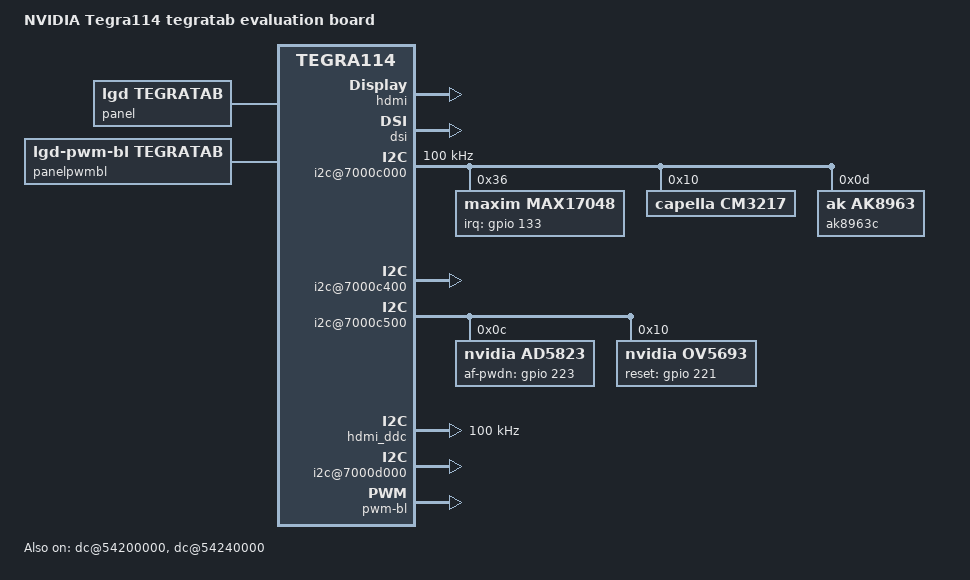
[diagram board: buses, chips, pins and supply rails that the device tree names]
/*
 * Copyright (c) 2013-2014, NVIDIA CORPORATION.  All rights reserved.
 *
 * This program is free software; you can redistribute it and/or modify it
 * under the terms and conditions of the GNU General Public License,
 * version 2, as published by the Free Software Foundation.
 *
 * This program is distributed in the hope it will be useful, but WITHOUT
 * ANY WARRANTY; without even the implied warranty of MERCHANTABILITY or
 * FITNESS FOR A PARTICULAR PURPOSE.  See the GNU General Public License for
 * more details.
 *
 * You should have received a copy of the GNU General Public License
 * along with this program.  If not, see <http://www.gnu.org/licenses/>.
 */

/dts-v1/;

/include/ "tegra114.dtsi"

/ {
	model = "NVIDIA Tegra114 tegratab evaluation board";
	compatible = "nvidia,tegratab", "nvidia,tegra114";

	gpio@6000d000 {
		status = "okay";
	};

	interrupt-controller@50041000 {
		status = "okay";
	};

	pinmux {
		pinctrl-names = "default";
		pinctrl-0 = <&state_default>;

		state_default: pinmux {
			clk1_out_pw4 {
				nvidia,pins = "clk1_out_pw4";
				nvidia,function = "extperiph1";
				nvidia,pull = <0>;
				nvidia,tristate = <0>;
				nvidia,enable-input = <0>;
			};
			dap1_din_pn1 {
				nvidia,pins = "dap1_din_pn1";
				nvidia,function = "i2s0";
				nvidia,pull = <0>;
				nvidia,tristate = <1>;
				nvidia,enable-input = <1>;
			};
			dap1_dout_pn2 {
				nvidia,pins = "dap1_dout_pn2",
						"dap1_fs_pn0",
						"dap1_sclk_pn3";
				nvidia,function = "i2s0";
				nvidia,pull = <0>;
				nvidia,tristate = <0>;
				nvidia,enable-input = <1>;
			};
			dap2_din_pa4 {
				nvidia,pins = "dap2_din_pa4";
				nvidia,function = "i2s1";
				nvidia,pull = <0>;
				nvidia,tristate = <1>;
				nvidia,enable-input = <1>;
			};
			dap2_dout_pa5 {
				nvidia,pins = "dap2_dout_pa5",
						"dap2_fs_pa2",
						"dap2_sclk_pa3";
				nvidia,function = "i2s1";
				nvidia,pull = <0>;
				nvidia,tristate = <0>;
				nvidia,enable-input = <1>;
			};
			dap4_din_pp5 {
				nvidia,pins = "dap4_din_pp5",
						"dap4_dout_pp6",
						"dap4_fs_pp4",
						"dap4_sclk_pp7";
				nvidia,function = "i2s3";
				nvidia,pull = <0>;
				nvidia,tristate = <0>;
				nvidia,enable-input = <1>;
			};
			dvfs_pwm_px0 {
				nvidia,pins = "dvfs_pwm_px0",
						"dvfs_clk_px2";
				nvidia,function = "cldvfs";
				nvidia,pull = <0>;
				nvidia,tristate = <0>;
				nvidia,enable-input = <0>;
			};
			ulpi_clk_py0 {
				nvidia,pins = "ulpi_clk_py0",
						"ulpi_data0_po1",
						"ulpi_data1_po2",
						"ulpi_data2_po3",
						"ulpi_data3_po4",
						"ulpi_data4_po5",
						"ulpi_data5_po6",
						"ulpi_data6_po7",
						"ulpi_data7_po0";
				nvidia,function = "ulpi";
				nvidia,pull = <0>;
				nvidia,tristate = <0>;
				nvidia,enable-input = <1>;
			};
			ulpi_dir_py1 {
				nvidia,pins = "ulpi_dir_py1",
						"ulpi_nxt_py2";
				nvidia,function = "ulpi";
				nvidia,pull = <0>;
				nvidia,tristate = <1>;
				nvidia,enable-input = <1>;
			};
			ulpi_stp_py3 {
				nvidia,pins = "ulpi_stp_py3";
				nvidia,function = "ulpi";
				nvidia,pull = <0>;
				nvidia,tristate = <0>;
				nvidia,enable-input = <0>;
			};
			cam_i2c_scl_pbb1 {
				nvidia,pins = "cam_i2c_scl_pbb1",
						"cam_i2c_sda_pbb2";
				nvidia,function = "i2c3";
				nvidia,pull = <0>;
				nvidia,tristate = <0>;
				nvidia,enable-input = <1>;
				nvidia,lock = <0>;
				nvidia,open-drain = <0>;
			};
			cam_mclk_pcc0 {
				nvidia,pins = "cam_mclk_pcc0",
						"pbb0";
				nvidia,function = "vi_alt3";
				nvidia,pull = <0>;
				nvidia,tristate = <0>;
				nvidia,enable-input = <0>;
				nvidia,lock = <0>;
			};
			gen2_i2c_scl_pt5 {
				nvidia,pins = "gen2_i2c_scl_pt5",
						"gen2_i2c_sda_pt6";
				nvidia,function = "i2c2";
				nvidia,pull = <0>;
				nvidia,tristate = <0>;
				nvidia,enable-input = <1>;
				nvidia,lock = <0>;
				nvidia,open-drain = <0>;
			};
			gmi_a16_pj7 {
				nvidia,pins = "gmi_a16_pj7";
				nvidia,function = "uartd";
				nvidia,pull = <0>;
				nvidia,tristate = <0>;
				nvidia,enable-input = <0>;
			};
			gmi_a17_pb0 {
				nvidia,pins = "gmi_a17_pb0",
						"gmi_a18_pb1";
				nvidia,function = "uartd";
				nvidia,pull = <0>;
				nvidia,tristate = <1>;
				nvidia,enable-input = <1>;
			};
			gmi_a19_pk7 {
				nvidia,pins = "gmi_a19_pk7";
				nvidia,function = "uartd";
				nvidia,pull = <0>;
				nvidia,tristate = <0>;
				nvidia,enable-input = <0>;
			};
			gmi_ad5_pg5 {
				nvidia,pins = "gmi_ad5_pg5",
						"gmi_cs6_n_pi3",
						"gmi_wr_n_pi0";
				nvidia,function = "spi4";
				nvidia,pull = <0>;
				nvidia,tristate = <0>;
				nvidia,enable-input = <1>;
			};
			gmi_ad6_pg6 {
				nvidia,pins = "gmi_ad6_pg6",
						"gmi_ad7_pg7";
				nvidia,function = "spi4";
				nvidia,pull = <2>;
				nvidia,tristate = <0>;
				nvidia,enable-input = <1>;
			};
			gmi_ad12_ph4 {
				nvidia,pins = "gmi_ad12_ph4";
				nvidia,function = "rsvd4";
				nvidia,pull = <0>;
				nvidia,tristate = <0>;
				nvidia,enable-input = <0>;
			};
			gmi_ad9_ph1 {
				nvidia,pins = "gmi_ad9_ph1";
				nvidia,function = "pwm1";
				nvidia,pull = <0>;
				nvidia,tristate = <0>;
				nvidia,enable-input = <0>;
			};
			gmi_cs1_n_pj2 {
				nvidia,pins = "gmi_cs1_n_pj2",
						"gmi_oe_n_pi1";
				nvidia,function = "soc";
				nvidia,pull = <0>;
				nvidia,tristate = <1>;
				nvidia,enable-input = <1>;
			};
			clk2_out_pw5 {
				nvidia,pins = "clk2_out_pw5";
				nvidia,function = "extperiph2";
				nvidia,pull = <0>;
				nvidia,tristate = <0>;
				nvidia,enable-input = <0>;
			};
			sdmmc1_clk_pz0 {
				nvidia,pins = "sdmmc1_clk_pz0";
				nvidia,function = "sdmmc1";
				nvidia,pull = <0>;
				nvidia,tristate = <0>;
				nvidia,enable-input = <1>;
			};
			sdmmc1_cmd_pz1 {
				nvidia,pins = "sdmmc1_cmd_pz1",
						"sdmmc1_dat0_py7",
						"sdmmc1_dat1_py6",
						"sdmmc1_dat2_py5",
						"sdmmc1_dat3_py4";
				nvidia,function = "sdmmc1";
				nvidia,pull = <2>;
				nvidia,tristate = <0>;
				nvidia,enable-input = <1>;
			};
			sdmmc1_wp_n_pv3 {
				nvidia,pins = "sdmmc1_wp_n_pv3";
				nvidia,function = "spi4";
				nvidia,pull = <2>;
				nvidia,tristate = <0>;
				nvidia,enable-input = <0>;
			};
			sdmmc3_clk_pa6 {
				nvidia,pins = "sdmmc3_clk_pa6";
				nvidia,function = "sdmmc3";
				nvidia,pull = <0>;
				nvidia,tristate = <0>;
				nvidia,enable-input = <1>;
			};
			sdmmc3_cmd_pa7 {
				nvidia,pins = "sdmmc3_cmd_pa7",
						"sdmmc3_dat0_pb7",
						"sdmmc3_dat1_pb6",
						"sdmmc3_dat2_pb5",
						"sdmmc3_dat3_pb4",
						"kb_col4_pq4",
						"sdmmc3_clk_lb_out_pee4",
						"sdmmc3_clk_lb_in_pee5";
				nvidia,function = "sdmmc3";
				nvidia,pull = <2>;
				nvidia,tristate = <0>;
				nvidia,enable-input = <1>;
			};
			sdmmc4_clk_pcc4 {
				nvidia,pins = "sdmmc4_clk_pcc4";
				nvidia,function = "sdmmc4";
				nvidia,pull = <0>;
				nvidia,tristate = <0>;
				nvidia,enable-input = <1>;
			};
			sdmmc4_cmd_pt7 {
				nvidia,pins = "sdmmc4_cmd_pt7",
						"sdmmc4_dat0_paa0",
						"sdmmc4_dat1_paa1",
						"sdmmc4_dat2_paa2",
						"sdmmc4_dat3_paa3",
						"sdmmc4_dat4_paa4",
						"sdmmc4_dat5_paa5",
						"sdmmc4_dat6_paa6",
						"sdmmc4_dat7_paa7";
				nvidia,function = "sdmmc4";
				nvidia,pull = <2>;
				nvidia,tristate = <0>;
				nvidia,enable-input = <1>;
			};
			clk_32k_out_pa0 {
				nvidia,pins = "clk_32k_out_pa0";
				nvidia,function = "blink";
				nvidia,pull = <0>;
				nvidia,tristate = <0>;
				nvidia,enable-input = <0>;
			};
			kb_col0_pq0 {
				nvidia,pins = "kb_col0_pq0",
						"kb_col1_pq1",
						"kb_col2_pq2",
						"kb_row0_pr0",
						"kb_row1_pr1",
						"kb_row2_pr2";
				nvidia,function = "kbc";
				nvidia,pull = <2>;
				nvidia,tristate = <0>;
				nvidia,enable-input = <1>;
			};
			dap3_din_pp1 {
				nvidia,pins = "dap3_din_pp1",
						"dap3_sclk_pp3";
				nvidia,function = "displayb";
				nvidia,pull = <0>;
				nvidia,tristate = <1>;
				nvidia,enable-input = <0>;
			};
			pv0 {
				nvidia,pins = "pv0";
				nvidia,function = "rsvd4";
				nvidia,pull = <0>;
				nvidia,tristate = <1>;
				nvidia,enable-input = <0>;
			};
			kb_row7_pr7 {
				nvidia,pins = "kb_row7_pr7";
				nvidia,function = "rsvd2";
				nvidia,pull = <2>;
				nvidia,tristate = <0>;
				nvidia,enable-input = <1>;
			};
			kb_row10_ps2 {
				nvidia,pins = "kb_row10_ps2";
				nvidia,function = "uarta";
				nvidia,pull = <0>;
				nvidia,tristate = <1>;
				nvidia,enable-input = <1>;
			};
			kb_row9_ps1 {
				nvidia,pins = "kb_row9_ps1";
				nvidia,function = "uarta";
				nvidia,pull = <0>;
				nvidia,tristate = <0>;
				nvidia,enable-input = <0>;
			};
			pwr_i2c_scl_pz6 {
				nvidia,pins = "pwr_i2c_scl_pz6",
						"pwr_i2c_sda_pz7";
				nvidia,function = "i2cpwr";
				nvidia,pull = <0>;
				nvidia,tristate = <0>;
				nvidia,enable-input = <1>;
				nvidia,lock = <0>;
				nvidia,open-drain = <0>;
			};
			sys_clk_req_pz5 {
				nvidia,pins = "sys_clk_req_pz5";
				nvidia,function = "sysclk";
				nvidia,pull = <0>;
				nvidia,tristate = <0>;
				nvidia,enable-input = <0>;
			};
			core_pwr_req {
				nvidia,pins = "core_pwr_req";
				nvidia,function = "pwron";
				nvidia,pull = <0>;
				nvidia,tristate = <0>;
				nvidia,enable-input = <0>;
			};
			cpu_pwr_req {
				nvidia,pins = "cpu_pwr_req";
				nvidia,function = "cpu";
				nvidia,pull = <0>;
				nvidia,tristate = <0>;
				nvidia,enable-input = <0>;
			};
			pwr_int_n {
				nvidia,pins = "pwr_int_n";
				nvidia,function = "pmi";
				nvidia,pull = <0>;
				nvidia,tristate = <1>;
				nvidia,enable-input = <1>;
			};
			reset_out_n {
				nvidia,pins = "reset_out_n";
				nvidia,function = "reset_out_n";
				nvidia,pull = <0>;
				nvidia,tristate = <0>;
				nvidia,enable-input = <0>;
			};
			clk3_out_pee0 {
				nvidia,pins = "clk3_out_pee0";
				nvidia,function = "extperiph3";
				nvidia,pull = <0>;
				nvidia,tristate = <0>;
				nvidia,enable-input = <0>;
			};
			gen1_i2c_scl_pc4 {
				nvidia,pins = "gen1_i2c_scl_pc4",
						"gen1_i2c_sda_pc5";
				nvidia,function = "i2c1";
				nvidia,pull = <0>;
				nvidia,tristate = <0>;
				nvidia,enable-input = <1>;
				nvidia,lock = <0>;
				nvidia,open-drain = <0>;
			};
			uart2_cts_n_pj5 {
				nvidia,pins = "uart2_cts_n_pj5";
				nvidia,function = "uartb";
				nvidia,pull = <0>;
				nvidia,tristate = <1>;
				nvidia,enable-input = <1>;
			};
			uart2_rts_n_pj6 {
				nvidia,pins = "uart2_rts_n_pj6";
				nvidia,function = "uartb";
				nvidia,pull = <0>;
				nvidia,tristate = <0>;
				nvidia,enable-input = <0>;
			};
			uart2_rxd_pc3 {
				nvidia,pins = "uart2_rxd_pc3";
				nvidia,function = "irda";
				nvidia,pull = <0>;
				nvidia,tristate = <1>;
				nvidia,enable-input = <1>;
			};
			uart2_txd_pc2 {
				nvidia,pins = "uart2_txd_pc2";
				nvidia,function = "irda";
				nvidia,pull = <0>;
				nvidia,tristate = <0>;
				nvidia,enable-input = <0>;
			};
			uart3_cts_n_pa1 {
				nvidia,pins = "uart3_cts_n_pa1",
						"uart3_rxd_pw7";
				nvidia,function = "uartc";
				nvidia,pull = <0>;
				nvidia,tristate = <1>;
				nvidia,enable-input = <1>;
			};
			uart3_rts_n_pc0 {
				nvidia,pins = "uart3_rts_n_pc0",
						"uart3_txd_pw6";
				nvidia,function = "uartc";
				nvidia,pull = <0>;
				nvidia,tristate = <0>;
				nvidia,enable-input = <0>;
			};
			owr {
				nvidia,pins = "owr";
				nvidia,function = "owr";
				nvidia,pull = <0>;
				nvidia,tristate = <0>;
				nvidia,enable-input = <1>;
			};
			hdmi_cec_pee3 {
				nvidia,pins = "hdmi_cec_pee3";
				nvidia,function = "cec";
				nvidia,pull = <0>;
				nvidia,tristate = <0>;
				nvidia,enable-input = <1>;
				nvidia,lock = <0>;
				nvidia,open-drain = <0>;
			};
			ddc_scl_pv4 {
				nvidia,pins = "ddc_scl_pv4",
						"ddc_sda_pv5";
				nvidia,function = "i2c4";
				nvidia,pull = <0>;
				nvidia,tristate = <0>;
				nvidia,enable-input = <1>;
				nvidia,lock = <0>;
				nvidia,rcv-sel = <1>;
			};
			spdif_in_pk6 {
				nvidia,pins = "spdif_in_pk6";
				nvidia,function = "usb";
				nvidia,pull = <2>;
				nvidia,tristate = <0>;
				nvidia,enable-input = <1>;
				nvidia,lock = <0>;
			};
			usb_vbus_en0_pn4 {
				nvidia,pins = "usb_vbus_en0_pn4";
				nvidia,function = "usb";
				nvidia,pull = <2>;
				nvidia,tristate = <0>;
				nvidia,enable-input = <1>;
				nvidia,lock = <0>;
				nvidia,open-drain = <1>;
			};
			gpio_x6_aud_px6 {
				nvidia,pins = "gpio_x6_aud_px6";
				nvidia,function = "spi6";
				nvidia,pull = <2>;
				nvidia,tristate = <1>;
				nvidia,enable-input = <1>;
			};
			gpio_x4_aud_px4 {
				nvidia,pins = "gpio_x4_aud_px4",
						"gpio_x7_aud_px7";
				nvidia,function = "rsvd1";
				nvidia,pull = <1>;
				nvidia,tristate = <0>;
				nvidia,enable-input = <0>;
			};
			gpio_x5_aud_px5 {
				nvidia,pins = "gpio_x5_aud_px5";
				nvidia,function = "rsvd1";
				nvidia,pull = <2>;
				nvidia,tristate = <0>;
				nvidia,enable-input = <1>;
			};
			gpio_w2_aud_pw2 {
				nvidia,pins = "gpio_w2_aud_pw2";
				nvidia,function = "rsvd2";
				nvidia,pull = <2>;
				nvidia,tristate = <0>;
				nvidia,enable-input = <1>;
			};
			gpio_w3_aud_pw3 {
				nvidia,pins = "gpio_w3_aud_pw3";
				nvidia,function = "spi6";
				nvidia,pull = <2>;
				nvidia,tristate = <0>;
				nvidia,enable-input = <1>;
			};
			gpio_x1_aud_px1 {
				nvidia,pins = "gpio_x1_aud_px1";
				nvidia,function = "rsvd4";
				nvidia,pull = <1>;
				nvidia,tristate = <0>;
				nvidia,enable-input = <1>;
			};
			gpio_x3_aud_px3 {
				nvidia,pins = "gpio_x3_aud_px3";
				nvidia,function = "rsvd4";
				nvidia,pull = <2>;
				nvidia,tristate = <0>;
				nvidia,enable-input = <1>;
			};
			dap3_fs_pp0 {
				nvidia,pins = "dap3_fs_pp0";
				nvidia,function = "i2s2";
				nvidia,pull = <1>;
				nvidia,tristate = <0>;
				nvidia,enable-input = <0>;
			};
			dap3_dout_pp2 {
				nvidia,pins = "dap3_dout_pp2";
				nvidia,function = "i2s2";
				nvidia,pull = <1>;
				nvidia,tristate = <0>;
				nvidia,enable-input = <0>;
			};
			pv1 {
				nvidia,pins = "pv1";
				nvidia,function = "rsvd1";
				nvidia,pull = <0>;
				nvidia,tristate = <0>;
				nvidia,enable-input = <1>;
			};
			pbb3 {
				nvidia,pins = "pbb3",
						"pbb5",
						"pbb6",
						"pbb7";
				nvidia,function = "rsvd4";
				nvidia,pull = <1>;
				nvidia,tristate = <0>;
				nvidia,enable-input = <0>;
			};
			pcc1 {
				nvidia,pins = "pcc1",
						"pcc2";
				nvidia,function = "rsvd4";
				nvidia,pull = <1>;
				nvidia,tristate = <0>;
				nvidia,enable-input = <1>;
			};
			gmi_ad0_pg0 {
				nvidia,pins = "gmi_ad0_pg0",
						"gmi_ad1_pg1";
				nvidia,function = "gmi";
				nvidia,pull = <0>;
				nvidia,tristate = <0>;
				nvidia,enable-input = <0>;
			};
			gmi_ad10_ph2 {
				nvidia,pins = "gmi_ad10_ph2",
						"gmi_ad11_ph3",
						"gmi_ad13_ph5",
						"gmi_ad8_ph0",
						"gmi_clk_pk1";
				nvidia,function = "gmi";
				nvidia,pull = <1>;
				nvidia,tristate = <0>;
				nvidia,enable-input = <0>;
			};
			gmi_ad2_pg2 {
				nvidia,pins = "gmi_ad2_pg2",
						"gmi_ad3_pg3";
				nvidia,function = "gmi";
				nvidia,pull = <0>;
				nvidia,tristate = <0>;
				nvidia,enable-input = <1>;
			};
			gmi_adv_n_pk0 {
				nvidia,pins = "gmi_adv_n_pk0",
						"gmi_cs0_n_pj0",
						"gmi_cs2_n_pk3",
						"gmi_cs4_n_pk2",
						"gmi_cs7_n_pi6",
						"gmi_dqs_p_pj3",
						"gmi_iordy_pi5",
						"gmi_wp_n_pc7";
				nvidia,function = "gmi";
				nvidia,pull = <2>;
				nvidia,tristate = <0>;
				nvidia,enable-input = <1>;
			};
			gmi_cs3_n_pk4 {
				nvidia,pins = "gmi_cs3_n_pk4";
				nvidia,function = "gmi";
				nvidia,pull = <2>;
				nvidia,tristate = <0>;
				nvidia,enable-input = <0>;
			};
			clk2_req_pcc5 {
				nvidia,pins = "clk2_req_pcc5";
				nvidia,function = "rsvd4";
				nvidia,pull = <0>;
				nvidia,tristate = <0>;
				nvidia,enable-input = <0>;
			};
			kb_col3_pq3 {
				nvidia,pins = "kb_col3_pq3",
						"kb_col6_pq6",
						"kb_col7_pq7";
				nvidia,function = "kbc";
				nvidia,pull = <2>;
				nvidia,tristate = <0>;
				nvidia,enable-input = <0>;
			};
			kb_col5_pq5 {
				nvidia,pins = "kb_col5_pq5";
				nvidia,function = "kbc";
				nvidia,pull = <2>;
				nvidia,tristate = <0>;
				nvidia,enable-input = <1>;
			};
			kb_row3_pr3 {
				nvidia,pins = "kb_row3_pr3",
						"kb_row4_pr4",
						"kb_row6_pr6",
						"kb_row8_ps0";
				nvidia,function = "kbc";
				nvidia,pull = <1>;
				nvidia,tristate = <0>;
				nvidia,enable-input = <1>;
			};
			clk3_req_pee1 {
				nvidia,pins = "clk3_req_pee1";
				nvidia,function = "rsvd4";
				nvidia,pull = <0>;
				nvidia,tristate = <0>;
				nvidia,enable-input = <0>;
			};
			pu4 {
				nvidia,pins = "pu4";
				nvidia,function = "displayb";
				nvidia,pull = <0>;
				nvidia,tristate = <0>;
				nvidia,enable-input = <0>;
			};
			pu5 {
				nvidia,pins = "pu5",
						"pu6";
				nvidia,function = "displayb";
				nvidia,pull = <0>;
				nvidia,tristate = <0>;
				nvidia,enable-input = <1>;
			};
			hdmi_int_pn7 {
				nvidia,pins = "hdmi_int_pn7";
				nvidia,function = "rsvd1";
				nvidia,pull = <1>;
				nvidia,tristate = <0>;
				nvidia,enable-input = <1>;
			};
			clk1_req_pee2 {
				nvidia,pins = "clk1_req_pee2",
						"usb_vbus_en1_pn5";
				nvidia,function = "rsvd4";
				nvidia,pull = <1>;
				nvidia,tristate = <1>;
				nvidia,enable-input = <0>;
			};

			drive_sdio1 {
				nvidia,pins = "drive_sdio1";
				nvidia,high-speed-mode = <1>;
				nvidia,schmitt = <0>;
				nvidia,low-power-mode = <3>;
				nvidia,pull-down-strength = <36>;
				nvidia,pull-up-strength = <20>;
				nvidia,slew-rate-rising = <2>;
				nvidia,slew-rate-falling = <2>;
			};
			drive_sdio3 {
				nvidia,pins = "drive_sdio3";
				nvidia,high-speed-mode = <1>;
				nvidia,schmitt = <0>;
				nvidia,low-power-mode = <3>;
				nvidia,pull-down-strength = <22>;
				nvidia,pull-up-strength = <36>;
				nvidia,slew-rate-rising = <0>;
				nvidia,slew-rate-falling = <0>;
			};
			drive_gma {
				nvidia,pins = "drive_gma";
				nvidia,high-speed-mode = <1>;
				nvidia,schmitt = <0>;
				nvidia,low-power-mode = <3>;
				nvidia,pull-down-strength = <2>;
				nvidia,pull-up-strength = <1>;
				nvidia,slew-rate-rising = <0>;
				nvidia,slew-rate-falling = <0>;
				nvidia,drive-type = <1>;
			};
		};
	};

	host1x {
		compatible = "nvidia,tegra114-host1x", "simple-bus";
		reg = <0x50000000 0x00024000>;
		interrupts = <0 65 0x04   /* mpcore syncpt */
			      0 67 0x04>; /* mpcore general */

		#address-cells = <1>;
		#size-cells = <1>;

		ranges = <0x54000000 0x54000000 0x01000000>;

		vi {
			compatible = "nvidia,tegra114-vi";
			reg = <0x54080000 0x00040000>;
		};

		epp {
			compatible = "nvidia,tegra114-epp";
			reg = <0x540c0000 0x00040000>;
		};

		isp {
			compatible = "nvidia,tegra114-isp";
			reg = <0x54100000 0x00040000>;
		};

		gr2d {
			compatible = "nvidia,tegra114-gr2d";
			reg = <0x54140000 0x00040000>;
		};

		gr3d {
			compatible = "nvidia,tegra114-gr3d";
			reg = <0x54180000 0x00040000>;
		};

		dc@54200000 {
			compatible = "nvidia,tegra114-dc";
			reg = <0x54200000 0x00040000>;
			interrupts = <0 73 0x04>;
			status = "disabled";

			rgb {
				status = "disabled";
			};
		};

		dc@54240000 {
			compatible = "nvidia,tegra114-dc";
			reg = <0x54240000 0x00040000>;
			interrupts = <0 74 0x04>;
			status = "disabled";

			rgb {
				status = "disabled";
			};
		};

		hdmi {
			compatible = "nvidia,tegra114-hdmi";
			reg = <0x54280000 0x00040000>;
			interrupts = <0 75 0x04>;
			status = "disabled";
		};

		tvo {
			compatible = "nvidia,tegra114-tvo";
			reg = <0x542c0000 0x00040000>;
			interrupts = <0 76 0x04>;
			status = "disabled";
		};

		dsi {
			compatible = "nvidia,tegra114-dsi";
			reg = <0x54300000 0x00040000>;
			status = "disabled";
		};

		msenc {
			compatible = "nvidia,tegra114-msenc";
			reg = <0x544c0000 0x00040000>;
		};

		tsec {
			compatible = "nvidia,tegra114-tsec";
			reg = <0x54500000 0x00040000>;
		};
	};

	/* GEN1 */
	i2c@7000c000 {
		status = "okay";

		max17048@36 {
			compatible = "maxim,max17048";
			reg = <0x36>;
			interrupt-parent = <&gpio>;
			interrupts = <133 0x04>;	/* gpio PQ5 */
			alert-threshold = <1>;		/* 1% SOC */
			one-percent-alerts = <1>;
			valert-max = <5100>;		/* not use */
			valert-min = <3240>;		/* 3.24V */
			vreset-threshold = <2400>;
			vreset-disable = <1>;		/* not use */
			hib-threshold = <48>;		/* 9.984%/hr */
			hib-active-threshold = <128>;	/* 160mV */
			bits = <19>;
			rcomp = <105>;
			rcomp-seg = <0x0080>;
			soccheck-a = <233>;
			soccheck-b = <235>;
			ocvtest = <55824>;
			minus_t_co_hot = <1125>;	/* -1.125 */
			minus_t_co_cold = <7625>;	/* -7.625 */
			data-tbl = <0xAA 0x30 0xB7 0x80 0xB8 0xD0 0xBA 0xC0
				0xBB 0xC0 0xBC 0x30 0xBC 0xB0 0xBD 0x60
				0xBE 0x10 0xBF 0x40 0xC0 0x30 0xC3 0x80
				0xC5 0x00 0xC7 0x60 0xCB 0x50 0xD0 0x10
				0x03 0x00 0x30 0xC0 0x1C 0x40 0x2C 0x00
				0x70 0xC0 0x51 0x40 0x43 0xE0 0x43 0xC0
				0x29 0xC0 0x2F 0xC0 0x17 0xE0 0x12 0xE0
				0x1C 0x20 0x13 0x80 0x0E 0x00 0x0E 0x00>;
			read_batt_id = <1>;
			set_current_threshold = "ina230";
			current_normal = <4500>;	/* 4.5A */
			current_threshold_num = <2>;
			current_threshold_soc = <4 8>;
			current_threshold = <1800 2500>;
			sysedp_throttle = "sysedp_lite";
			sysedp_throttle_num = <2>;
			sysedp_throttle_soc = <4 8>;
			sysedp_throttle_power = <10000 10500>;
		};
	};

	/* GEN2 */
	i2c@7000c400 {
		status = "okay";
	};

	/* CAM */
	i2c@7000c500 {
		status = "okay";
	};

	/* DDC */
	i2c@7000c700 {
		status = "okay";
	};

	/* PWR */
	i2c@7000d000 {
		status = "okay";
	};

	memory-controller@7001b000 {
		emc-table@12750 {
			compatible = "nvidia,tegra11-emc-table";
			reg = <12750>;
			clock-frequency = <12750>;
			nvidia,revision = <0x42>;
			nvidia,emc-min-mv = <900>;
			nvidia,source = "pll_p";
			nvidia,src-sel-reg = <0x4400003e>;
			nvidia,burst-regs-num = <100>;
			nvidia,emc-trimmers-num = <30>;
			nvidia,burst-up-down-regs-num = <11>;
			nvidia,emc-registers = <0x00000000 0x00000003
					0x00000000 0x00000000 0x00000000 0x00000004
					0x0000000a 0x00000003 0x0000000b 0x00000000
					0x00000000 0x00000003 0x00000001 0x00000000
					0x00000005 0x0000000f 0x00000006 0x00010000
					0x00000000 0x00000004 0x0000000f 0x00000060
					0x00000000 0x00000018 0x00000002 0x00000002
					0x00000001 0x00000000 0x00000007 0x0000000f
					0x00000005 0x00000005 0x00000004 0x00000004
					0x00000004 0x00000004 0x00000000 0x00000004
					0x00000005 0x00000064 0x00000005 0x00000020
					0x00000000 0x0000aa88 0x002c00a0 0x00008000
					0x00064000 0x00064000 0x00064000 0x00064000
					0x00000000 0x00000000 0x00000000 0x00000000
					0x00000000 0x00000000 0x00000000 0x00000000
					0x001112a0 0x00000000 0x0000a11c 0x00000000
					0x77ffc085 0x81f1f108 0x03037504 0x0000003f
					0x0000003f 0x00000007 0x02000000 0x00000802
					0x00000000 0x00000042 0x000c000c 0x000c000c
					0x00000000 0x00000000 0x00000000 0x00000000
					0x800001c5 0x1f7df7df 0x0000001f 0x40040001
					0x8000003f 0x00000001 0x00000001 0x00000002
					0x00000000 0x00000001 0x00000001 0x00000002
					0x00000008 0x00000002 0x00000001 0x00000003
					0x00000006 0x06030102 0x000a0402 0x77e30303
					0x001f0000 0x00040320>;
			nvidia,emc-trimmers-0 = <0x00000000 0x00000006
					0x00000006 0x00000004 0x00000004 0x00064000
					0x00000009 0x00000000 0x0000000d 0x00249249
					0x20820800 0x0007c000 0xa0f10f0f 0x00000000
					0x00000b0b 0x00000000 0x00000000 0x00000000
					0x00064000 0x00064000 0x00064000 0x0007c000
					0x0007c000 0x0007c000 0x00000000 0x00000000
					0x00000000 0x00000000 0x00000000 0x00000000>;
			nvidia,emc-trimmers-1 = <0x00000000 0x00000006
					0x00000006 0x00000004 0x00000004 0x00064000
					0x00000009 0x00000000 0x0000000d 0x00249249
					0x20820800 0x0007c000 0xa8f10f0f 0x00000000
					0x00000b0b 0x00000000 0x00000000 0x00000000
					0x00064000 0x00064000 0x00064000 0x0007c000
					0x0007c000 0x0007c000 0x00000000 0x00000000
					0x00000000 0x00000000 0x00000000 0x00000000>;
			nvidia,emc-burst-up-down-regs = <0x00000007 0x00ff00ff
					0x00ff00ff 0x00ff00ff 0x000000ff 0x00ff00ff
					0x00ff00ff 0x000000ff 0x00ff00ff 0x00ff00ff
					0x00ff00ff 0x4E564441 0x04010700 0x02000400
					12750>;
			nvidia,emc-zcal-cnt-long = <0x00000042>;
			nvidia,emc-acal-interval = <0x001fffff>;
			nvidia,emc-cfg = <0x7324000e>;
			nvidia,emc-mode-reset = <0x80001221>;
			nvidia,emc-mode-1 = <0x80100003>;
			nvidia,emc-mode-2 = <0x80200008>;
			nvidia,emc-mode-4 = <0x00000000>;
			nvidia,emc-clock-latency-change = <57820>;
		};
		emc-table@20400 {
			compatible = "nvidia,tegra11-emc-table";
			reg = <20400>;
			clock-frequency = <20400>;
			nvidia,revision = <0x42>;
			nvidia,emc-min-mv = <900>;
			nvidia,source = "pll_p";
			nvidia,src-sel-reg = <0x44000026>;
			nvidia,burst-regs-num = <100>;
			nvidia,emc-trimmers-num = <30>;
			nvidia,burst-up-down-regs-num = <11>;
			nvidia,emc-registers = <0x00000000 0x00000003
					0x00000000 0x00000000 0x00000000 0x00000004
					0x0000000a 0x00000003 0x0000000b 0x00000000
					0x00000000 0x00000003 0x00000001 0x00000000
					0x00000005 0x0000000f 0x00000006 0x00010000
					0x00000000 0x00000004 0x0000000f 0x0000009a
					0x00000000 0x00000026 0x00000002 0x00000002
					0x00000001 0x00000000 0x00000007 0x0000000f
					0x00000005 0x00000005 0x00000004 0x00000004
					0x00000004 0x00000004 0x00000000 0x00000004
					0x00000005 0x000000a0 0x00000005 0x00000020
					0x00000000 0x0000aa88 0x002c00a0 0x00008000
					0x00064000 0x00064000 0x00064000 0x00064000
					0x00000000 0x00000000 0x00000000 0x00000000
					0x00000000 0x00000000 0x00000000 0x00000000
					0x001112a0 0x00000000 0x0000a11c 0x00000000
					0x77ffc085 0x81f1f108 0x03037504 0x0000003f
					0x0000003f 0x0000000b 0x02000000 0x00000802
					0x00000000 0x00000042 0x000c000c 0x000c000c
					0x00000000 0x00000000 0x00000000 0x00000000
					0x8000023a 0x1f7df7df 0x0000001f 0x40020001
					0x80000046 0x00000001 0x00000001 0x00000002
					0x00000000 0x00000001 0x00000001 0x00000002
					0x00000008 0x00000002 0x00000001 0x00000003
					0x00000006 0x06030102 0x000a0402 0x75430303
					0x001f0000 0x00040320>;
			nvidia,emc-trimmers-0 = <0x00000000 0x00000006
					0x00000006 0x00000004 0x00000004 0x00064000
					0x00000009 0x00000000 0x0000000d 0x00249249
					0x20820800 0x0007c000 0xa0f10f0f 0x00000000
					0x00000b0b 0x00000000 0x00000000 0x00000000
					0x00064000 0x00064000 0x00064000 0x0007c000
					0x0007c000 0x0007c000 0x00000000 0x00000000
					0x00000000 0x00000000 0x00000000 0x00000000>;
			nvidia,emc-trimmers-1 = <0x00000000 0x00000006
					0x00000006 0x00000004 0x00000004 0x00064000
					0x00000009 0x00000000 0x0000000d 0x00249249
					0x20820800 0x0007c000 0xa8f10f0f 0x00000000
					0x00000b0b 0x00000000 0x00000000 0x00000000
					0x00064000 0x00064000 0x00064000 0x0007c000
					0x0007c000 0x0007c000 0x00000000 0x00000000
					0x00000000 0x00000000 0x00000000 0x00000000>;
			nvidia,emc-burst-up-down-regs = <0x0000000a 0x00ff00ff
					0x00ff00ff 0x00ff00ff 0x000000ff 0x00ff00ff
					0x00ff00ff 0x000000ff 0x00ff00ff 0x00ff00ff
					0x00ff00ff 0x4E564441 0x04010700 0x02000400
					20400>;
			nvidia,emc-zcal-cnt-long = <0x00000042>;
			nvidia,emc-acal-interval = <0x001fffff>;
			nvidia,emc-cfg = <0x7324000e>;
			nvidia,emc-mode-reset = <0x80001221>;
			nvidia,emc-mode-1 = <0x80100003>;
			nvidia,emc-mode-2 = <0x80200008>;
			nvidia,emc-mode-4 = <0x00000000>;
			nvidia,emc-clock-latency-change = <35610>;
		};
		emc-table@40800 {
			compatible = "nvidia,tegra11-emc-table";
			reg = <40800>;
			clock-frequency = <40800>;
			nvidia,revision = <0x42>;
			nvidia,emc-min-mv = <900>;
			nvidia,source = "pll_p";
			nvidia,src-sel-reg = <0x44000012>;
			nvidia,burst-regs-num = <100>;
			nvidia,emc-trimmers-num = <30>;
			nvidia,burst-up-down-regs-num = <11>;
			nvidia,emc-registers = <0x00000001 0x00000006
					0x00000000 0x00000001 0x00000000 0x00000004
					0x0000000a 0x00000003 0x0000000b 0x00000000
					0x00000000 0x00000003 0x00000001 0x00000000
					0x00000005 0x0000000f 0x00000006 0x00010000
					0x00000000 0x00000004 0x0000000f 0x00000134
					0x00000000 0x0000004d 0x00000002 0x00000002
					0x00000001 0x00000000 0x00000007 0x0000000f
					0x00000007 0x00000007 0x00000004 0x00000004
					0x00000004 0x00000004 0x00000000 0x00000004
					0x00000005 0x0000013f 0x00000005 0x00000020
					0x00000000 0x0000aa88 0x002c00a0 0x00008000
					0x00064000 0x00064000 0x00064000 0x00064000
					0x00000000 0x00000000 0x00000000 0x00000000
					0x00000000 0x00000000 0x00000000 0x00000000
					0x001112a0 0x00000000 0x0000a11c 0x00000000
					0x77ffc085 0x81f1f108 0x03037504 0x0000003f
					0x0000003f 0x00000015 0x02000000 0x00000802
					0x00000000 0x00000042 0x000c000c 0x000c000c
					0x00000000 0x00000000 0x00000000 0x00000000
					0x80000370 0x1f7df7df 0x0000001f 0xa0000001
					0x8000005b 0x00000001 0x00000001 0x00000002
					0x00000000 0x00000001 0x00000001 0x00000002
					0x00000008 0x00000002 0x00000001 0x00000003
					0x00000006 0x06030102 0x000a0402 0x73630303
					0x001f0000 0x00040320>;
			nvidia,emc-trimmers-0 = <0x00000000 0x00000006
					0x00000006 0x00000004 0x00000004 0x00064000
					0x00000009 0x00000000 0x0000000d 0x00249249
					0x20820800 0x0007c000 0xa0f10f0f 0x00000000
					0x00000b0b 0x00000000 0x00000000 0x00000000
					0x00064000 0x00064000 0x00064000 0x0007c000
					0x0007c000 0x0007c000 0x00000000 0x00000000
					0x00000000 0x00000000 0x00000000 0x00000000>;
			nvidia,emc-trimmers-1 = <0x00000000 0x00000006
					0x00000006 0x00000004 0x00000004 0x00064000
					0x00000009 0x00000000 0x0000000d 0x00249249
					0x20820800 0x0007c000 0xa8f10f0f 0x00000000
					0x00000b0b 0x00000000 0x00000000 0x00000000
					0x00064000 0x00064000 0x00064000 0x0007c000
					0x0007c000 0x0007c000 0x00000000 0x00000000
					0x00000000 0x00000000 0x00000000 0x00000000>;
			nvidia,emc-burst-up-down-regs = <0x00000015 0x00b000b0
					0x00b000c4 0x00d700eb 0x000000eb 0x00eb00eb
					0x00ff00eb 0x000000ff 0x00ff00ff 0x00ff00ff
					0x00ff00ff 0x4E564441 0x04010700 0x02000400
					40800>;
			nvidia,emc-zcal-cnt-long = <0x00000042>;
			nvidia,emc-acal-interval = <0x001fffff>;
			nvidia,emc-cfg = <0x7324000e>;
			nvidia,emc-mode-reset = <0x80001221>;
			nvidia,emc-mode-1 = <0x80100003>;
			nvidia,emc-mode-2 = <0x80200008>;
			nvidia,emc-mode-4 = <0x00000000>;
			nvidia,emc-clock-latency-change = <20850>;
		};
		emc-table@68000 {
			compatible = "nvidia,tegra11-emc-table";
			reg = <68000>;
			clock-frequency = <68000>;
			nvidia,revision = <0x42>;
			nvidia,emc-min-mv = <900>;
			nvidia,source = "pll_p";
			nvidia,src-sel-reg = <0x4400000a>;
			nvidia,burst-regs-num = <100>;
			nvidia,emc-trimmers-num = <30>;
			nvidia,burst-up-down-regs-num = <11>;
			nvidia,emc-registers = <0x00000003 0x0000000a
					0x00000000 0x00000002 0x00000000 0x00000004
					0x0000000a 0x00000003 0x0000000b 0x00000000
					0x00000000 0x00000003 0x00000001 0x00000000
					0x00000005 0x0000000f 0x00000006 0x00010000
					0x00000000 0x00000004 0x0000000f 0x00000202
					0x00000000 0x00000080 0x00000002 0x00000002
					0x00000001 0x00000000 0x00000008 0x0000000f
					0x0000000c 0x0000000c 0x00000004 0x00000004
					0x00000004 0x00000004 0x00000000 0x00000004
					0x00000005 0x00000213 0x00000005 0x00000020
					0x00000000 0x0000aa88 0x002c00a0 0x00008000
					0x00064000 0x00064000 0x00064000 0x00064000
					0x00000000 0x00000000 0x00000000 0x00000000
					0x00000000 0x00000000 0x00000000 0x00000000
					0x001112a0 0x00000000 0x0000a11c 0x00000000
					0x77ffc085 0x81f1f108 0x03037504 0x0000003f
					0x0000003f 0x00000022 0x02000000 0x00000802
					0x00000000 0x00000042 0x000c000c 0x000c000c
					0x00000000 0x00000000 0x00000000 0x00000000
					0x8000050e 0x1f7df7df 0x0000001f 0x00000001
					0x80000076 0x00000001 0x00000001 0x00000002
					0x00000000 0x00000001 0x00000001 0x00000002
					0x00000008 0x00000002 0x00000001 0x00000003
					0x00000006 0x06030102 0x000a0402 0x72c30403
					0x001f0000 0x00040320>;
			nvidia,emc-trimmers-0 = <0x00000000 0x00000006
					0x00000006 0x00000004 0x00000004 0x00064000
					0x00000009 0x00000000 0x0000000d 0x00249249
					0x20820800 0x0007c000 0xa0f10f0f 0x00000000
					0x00000b0b 0x00000000 0x00000000 0x00000000
					0x00064000 0x00064000 0x00064000 0x0007c000
					0x0007c000 0x0007c000 0x00000000 0x00000000
					0x00000000 0x00000000 0x00000000 0x00000000>;
			nvidia,emc-trimmers-1 = <0x00000000 0x00000006
					0x00000006 0x00000004 0x00000004 0x00064000
					0x00000009 0x00000000 0x0000000d 0x00249249
					0x20820800 0x0007c000 0xa8f10f0f 0x00000000
					0x00000b0b 0x00000000 0x00000000 0x00000000
					0x00064000 0x00064000 0x00064000 0x0007c000
					0x0007c000 0x0007c000 0x00000000 0x00000000
					0x00000000 0x00000000 0x00000000 0x00000000>;
			nvidia,emc-burst-up-down-regs = <0x00000023 0x00690069
					0x00690075 0x0081008d 0x0000008d 0x008d008d
					0x00bc008d 0x000000bc 0x00bc00bc 0x00ff00ff
					0x00ff00ff 0x4E564441 0x04010700 0x02000400
					68000>;
			nvidia,emc-zcal-cnt-long = <0x00000042>;
			nvidia,emc-acal-interval = <0x001fffff>;
			nvidia,emc-cfg = <0x7324000e>;
			nvidia,emc-mode-reset = <0x80001221>;
			nvidia,emc-mode-1 = <0x80100003>;
			nvidia,emc-mode-2 = <0x80200008>;
			nvidia,emc-mode-4 = <0x00000000>;
			nvidia,emc-clock-latency-change = <10720>;
		};
		emc-table@102000 {
			compatible = "nvidia,tegra11-emc-table";
			reg = <102000>;
			clock-frequency = <102000>;
			nvidia,revision = <0x42>;
			nvidia,emc-min-mv = <900>;
			nvidia,source = "pll_p";
			nvidia,src-sel-reg = <0x44000006>;
			nvidia,burst-regs-num = <100>;
			nvidia,emc-trimmers-num = <30>;
			nvidia,burst-up-down-regs-num = <11>;
			nvidia,emc-registers = <0x00000004 0x00000010
					0x00000000 0x00000003 0x00000001 0x00000004
					0x0000000a 0x00000003 0x0000000b 0x00000001
					0x00000001 0x00000003 0x00000001 0x00000000
					0x00000005 0x0000000f 0x00000006 0x00010000
					0x00000000 0x00000004 0x0000000f 0x00000303
					0x00000000 0x000000c0 0x00000002 0x00000002
					0x00000001 0x00000000 0x0000000d 0x0000000f
					0x00000012 0x00000012 0x00000004 0x00000004
					0x00000004 0x00000005 0x00000000 0x00000004
					0x00000005 0x0000031c 0x00000005 0x00000020
					0x00000000 0x0000aa88 0x002c00a0 0x00008000
					0x00064000 0x00064000 0x00064000 0x00064000
					0x00000000 0x00000000 0x00000000 0x00000000
					0x00000000 0x00000000 0x00000000 0x00000000
					0x001112a0 0x00000000 0x0000a11c 0x00000000
					0x77ffc085 0x81f1f108 0x03037504 0x0000003f
					0x0000003f 0x00000033 0x02000000 0x00000802
					0x00000000 0x00000042 0x000c000c 0x000c000c
					0x00000000 0x00000000 0x00000000 0x00000000
					0x80000713 0x1f7df7df 0x0000001f 0x08000001
					0x80000098 0x00000001 0x00000001 0x00000003
					0x00000000 0x00000002 0x00000001 0x00000002
					0x00000008 0x00000002 0x00000001 0x00000003
					0x00000006 0x06030102 0x000a0403 0x72830504
					0x001f0000 0x00040320>;
			nvidia,emc-trimmers-0 = <0x00000000 0x00000006
					0x00000006 0x00000004 0x00000004 0x00064000
					0x00000009 0x00000000 0x0000000d 0x00249249
					0x20820800 0x0007c000 0xa0f10f0f 0x00000000
					0x00000b0b 0x00000000 0x00000000 0x00000000
					0x00064000 0x00064000 0x00064000 0x0007c000
					0x0007c000 0x0007c000 0x00000000 0x00000000
					0x00000000 0x00000000 0x00000000 0x00000000>;
			nvidia,emc-trimmers-1 = <0x00000000 0x00000006
					0x00000006 0x00000004 0x00000004 0x00064000
					0x00000009 0x00000000 0x0000000d 0x00249249
					0x20820800 0x0007c000 0xa8f10f0f 0x00000000
					0x00000b0b 0x00000000 0x00000000 0x00000000
					0x00064000 0x00064000 0x00064000 0x0007c000
					0x0007c000 0x0007c000 0x00000000 0x00000000
					0x00000000 0x00000000 0x00000000 0x00000000>;
			nvidia,emc-burst-up-down-regs = <0x00000034 0x00460046
					0x0046004e 0x0056005e 0x0000005e 0x005e005e
					0x007d005e 0x0000007d 0x007d007d 0x00ff00ff
					0x00ff00ff 0x4E564441 0x04010700 0x02000400
					102000>;
			nvidia,emc-zcal-cnt-long = <0x00000042>;
			nvidia,emc-acal-interval = <0x001fffff>;
			nvidia,emc-cfg = <0x7324000e>;
			nvidia,emc-mode-reset = <0x80001221>;
			nvidia,emc-mode-1 = <0x80100003>;
			nvidia,emc-mode-2 = <0x80200008>;
			nvidia,emc-mode-4 = <0x00000000>;
			nvidia,emc-clock-latency-change = <6890>;
		};
		emc-table@204000 {
			compatible = "nvidia,tegra11-emc-table";
			reg = <204000>;
			clock-frequency = <204000>;
			nvidia,revision = <0x42>;
			nvidia,emc-min-mv = <900>;
			nvidia,source = "pll_p";
			nvidia,src-sel-reg = <0x44000002>;
			nvidia,burst-regs-num = <100>;
			nvidia,emc-trimmers-num = <30>;
			nvidia,burst-up-down-regs-num = <11>;
			nvidia,emc-registers = <0x00000009 0x00000020
					0x00000000 0x00000007 0x00000002 0x00000004
					0x0000000a 0x00000003 0x0000000b 0x00000002
					0x00000002 0x00000003 0x00000001 0x00000000
					0x00000005 0x0000000f 0x00000006 0x00010000
					0x00000000 0x00000004 0x0000000f 0x00000607
					0x00000000 0x00000181 0x00000002 0x00000002
					0x00000001 0x00000000 0x0000001d 0x0000000f
					0x00000023 0x00000023 0x00000004 0x00000004
					0x00000004 0x00000009 0x00000000 0x00000004
					0x00000005 0x00000638 0x00000006 0x00000020
					0x00000000 0x0000aa88 0x002c00a0 0x00008000
					0x00064000 0x00064000 0x00064000 0x00064000
					0x00000000 0x00000000 0x00000000 0x00000000
					0x00000000 0x00000000 0x00000000 0x00000000
					0x001112a0 0x00000000 0x0000a11c 0x00000000
					0x77ffc085 0x81f1f108 0x03037504 0x0000003f
					0x0000003f 0x00000000 0x02000000 0x00000802
					0x00020000 0x00000100 0x000c000c 0x000c000c
					0x00000000 0x00000000 0x00000000 0x00000000
					0x80000d22 0x1f7df7df 0x0000001f 0x01000003
					0x800000fe 0x00000001 0x00000001 0x00000005
					0x00000002 0x00000004 0x00000001 0x00000002
					0x00000008 0x00000002 0x00000001 0x00000003
					0x00000006 0x06030102 0x000a0405 0x72440a06
					0x001f0000 0x00040320>;
			nvidia,emc-trimmers-0 = <0x00000000 0x00000004
					0x00000007 0x00000004 0x00000004 0x00064000
					0x00000009 0x00000000 0x0000000d 0x00249249
					0x20820800 0x0007c000 0xa0f10f0f 0x00000000
					0x00000b0b 0x00000000 0x00000000 0x00000000
					0x00064000 0x00064000 0x00064000 0x0007c000
					0x0007c000 0x0007c000 0x00000000 0x00000000
					0x00000000 0x00000000 0x00000000 0x00000000>;
			nvidia,emc-trimmers-1 = <0x00000000 0x00000004
					0x00000007 0x00000004 0x00000004 0x00064000
					0x00000009 0x00000000 0x0000000d 0x00249249
					0x20820800 0x0007c000 0xa8f10f0f 0x00000000
					0x00000b0b 0x00000000 0x00000000 0x00000000
					0x00064000 0x00064000 0x00064000 0x0007c000
					0x0007c000 0x0007c000 0x00000000 0x00000000
					0x00000000 0x00000000 0x00000000 0x00000000>;
			nvidia,emc-burst-up-down-regs = <0x00000068 0x00230023
					0x00230027 0x002b002f 0x0000002f 0x002f002f
					0x003e002f 0x0000003e 0x003e003e 0x00ff00c8
					0x00ff00ff 0x4E564441 0x04010700 0x02000400
					204000>;
			nvidia,emc-zcal-cnt-long = <0x00000042>;
			nvidia,emc-acal-interval = <0x001fffff>;
			nvidia,emc-cfg = <0x7320000e>;
			nvidia,emc-mode-reset = <0x80001221>;
			nvidia,emc-mode-1 = <0x80100003>;
			nvidia,emc-mode-2 = <0x80200008>;
			nvidia,emc-mode-4 = <0x00000000>;
			nvidia,emc-clock-latency-change = <3420>;
		};
		emc-table@312000 {
			compatible = "nvidia,tegra11-emc-table";
			reg = <312000>;
			clock-frequency = <312000>;
			nvidia,revision = <0x42>;
			nvidia,emc-min-mv = <1000>;
			nvidia,source = "pll_c";
			nvidia,src-sel-reg = <0x24000002>;
			nvidia,burst-regs-num = <100>;
			nvidia,emc-trimmers-num = <30>;
			nvidia,burst-up-down-regs-num = <11>;
			nvidia,emc-registers = <0x0000000e 0x00000030
					0x00000000 0x00000009 0x00000003 0x00000004
					0x00000008 0x00000002 0x00000009 0x00000003
					0x00000003 0x00000002 0x00000001 0x00000000
					0x00000004 0x0000000f 0x00000006 0x00010000
					0x00000000 0x00000004 0x0000000f 0x00000941
					0x00000000 0x00000250 0x00000001 0x00000008
					0x00000001 0x00000000 0x0000002e 0x0000000e
					0x00000036 0x00000200 0x00000004 0x00000004
					0x00000004 0x0000000d 0x00000000 0x00000004
					0x00000005 0x00000982 0x00000000 0x00000020
					0x00000000 0x00005088 0x002c00a0 0x00008000
					0x00030000 0x00030000 0x00030000 0x00030000
					0x00000000 0x00000000 0x00000000 0x00000000
					0x00000000 0x00000000 0x00000000 0x00000000
					0x001112a0 0x00000000 0x0001013d 0x00000000
					0x77ffc085 0x81f1f108 0x03037504 0x00000000
					0x0000003f 0x00000000 0x02000000 0x00000802
					0x00020000 0x00000100 0x0190000c 0x0190000c
					0x00000000 0x00000000 0x00000000 0x00000000
					0x8000138d 0x1f7df7df 0x0000001f 0x0b000004
					0x8000016a 0x00000001 0x00000002 0x00000007
					0x00000004 0x00000006 0x00000001 0x00000002
					0x00000007 0x00000002 0x00000002 0x00000004
					0x00000006 0x06040202 0x000b0607 0x76e50f08
					0x001f0000 0x00040320>;
			nvidia,emc-trimmers-0 = <0x00000000 0x00000004
					0x00000006 0x00000005 0x00000004 0x00030000
					0x0000000b 0x00000000 0x0000000e 0x00249249
					0x20820800 0x0003c000 0xa0f10f0f 0x00048000
					0x00000909 0x00000000 0x00000000 0x00048000
					0x00030000 0x00030000 0x00030000 0x0003c000
					0x0003c000 0x0003c000 0x00000000 0x00000000
					0x00000000 0x00000000 0x00000000 0x00000000>;
			nvidia,emc-trimmers-1 = <0x00000000 0x00000004
					0x00000006 0x00000005 0x00000004 0x00030000
					0x0000000b 0x00000000 0x0000000e 0x00249249
					0x20820800 0x0003c000 0xa8f10f0f 0x00048000
					0x00000909 0x00000000 0x00000000 0x00048000
					0x00030000 0x00030000 0x00030000 0x0003c000
					0x0003c000 0x0003c000 0x00000000 0x00000000
					0x00000000 0x00000000 0x00000000 0x00000000>;
			nvidia,emc-burst-up-down-regs = <0x000000a0 0x00170017
					0x00170019 0x001c001e 0x0000001e 0x001e001e
					0x0029001e 0x00000029 0x00290029 0x00ff0082
					0x00ff00ff 0x4E564441 0x04010700 0x02000400
					312000>;
			nvidia,emc-zcal-cnt-long = <0x00000042>;
			nvidia,emc-acal-interval = <0x001fffff>;
			nvidia,emc-cfg = <0x5300000e>;
			nvidia,emc-mode-reset = <0x80000321>;
			nvidia,emc-mode-1 = <0x80100002>;
			nvidia,emc-mode-2 = <0x80200000>;
			nvidia,emc-mode-4 = <0x00000000>;
			nvidia,emc-clock-latency-change = <2180>;
		};
		emc-table@408000 {
			compatible = "nvidia,tegra11-emc-table";
			reg = <408000>;
			clock-frequency = <408000>;
			nvidia,revision = <0x42>;
			nvidia,emc-min-mv = <1000>;
			nvidia,source = "pll_p";
			nvidia,src-sel-reg = <0x44000000>;
			nvidia,burst-regs-num = <100>;
			nvidia,emc-trimmers-num = <30>;
			nvidia,burst-up-down-regs-num = <11>;
			nvidia,emc-registers = <0x00000012 0x00000040
					0x00000000 0x0000000d 0x00000004 0x00000005
					0x00000009 0x00000002 0x0000000c 0x00000004
					0x00000004 0x00000002 0x00000001 0x00000000
					0x00000004 0x0000000f 0x00000006 0x00010000
					0x00000000 0x00000004 0x00000010 0x00000c2e
					0x00000000 0x0000030b 0x00000001 0x00000008
					0x00000001 0x00000000 0x0000003d 0x00000011
					0x00000046 0x00000200 0x00000004 0x00000004
					0x00000004 0x00000011 0x00000000 0x00000004
					0x00000005 0x00000c6f 0x00000000 0x00000020
					0x00000000 0x00005088 0x002c0080 0x00008000
					0x00028000 0x00028000 0x00028000 0x00028000
					0x00000000 0x00000000 0x00000000 0x00000000
					0x00000000 0x00000000 0x00000000 0x00000000
					0x001112a0 0x00000000 0x0001013d 0x00000000
					0x77ffc085 0x81f1f108 0x03037504 0x00000000
					0x0000003f 0x00000000 0x02000000 0x00000802
					0x00020000 0x00000100 0x0181000c 0x0181000c
					0x00000000 0x00000000 0x00000000 0x00000000
					0x80001941 0x1f7df7df 0x0000001f 0x02000006
					0x80000190 0x00000001 0x00000002 0x0000000a
					0x00000006 0x00000008 0x00000001 0x00000002
					0x00000009 0x00000002 0x00000002 0x00000004
					0x00000006 0x06040202 0x000e070a 0x7547130b
					0x001f0000 0x00040320>;
			nvidia,emc-trimmers-0 = <0x00000000 0x00000004
					0x00000006 0x00000005 0x00000004 0x00028000
					0x0000000c 0x00000000 0x0000000e 0x00249249
					0x20820800 0x00028000 0xa0f10f0f 0x00028000
					0x00000606 0x00000000 0x00000000 0x00028000
					0x00028000 0x00028000 0x00028000 0x00028000
					0x00028000 0x00028000 0x00000000 0x00000000
					0x00000000 0x00000000 0x00000000 0x00000000>;
			nvidia,emc-trimmers-1 = <0x00000000 0x00000004
					0x00000006 0x00000005 0x00000004 0x00028000
					0x0000000c 0x00000000 0x0000000e 0x00249249
					0x20820800 0x00028000 0xa8f10f0f 0x00028000
					0x00000606 0x00000000 0x00000000 0x00028000
					0x00028000 0x00028000 0x00028000 0x00028000
					0x00028000 0x00028000 0x00000000 0x00000000
					0x00000000 0x00000000 0x00000000 0x00000000>;
			nvidia,emc-burst-up-down-regs = <0x000000d1 0x00110011
					0x00110013 0x00150017 0x00000017 0x00170017
					0x001f0017 0x0000001f 0x001f001f 0x00d30064
					0x00d300d3 0x4E564441 0x04010700 0x02000400
					408000>;
			nvidia,emc-zcal-cnt-long = <0x00000042>;
			nvidia,emc-acal-interval = <0x001fffff>;
			nvidia,emc-cfg = <0x53000006>;
			nvidia,emc-mode-reset = <0x80000731>;
			nvidia,emc-mode-1 = <0x80100002>;
			nvidia,emc-mode-2 = <0x80200008>;
			nvidia,emc-mode-4 = <0x00000000>;
			nvidia,emc-clock-latency-change = <1750>;
		};
		emc-table@528000 {
			compatible = "nvidia,tegra11-emc-table";
			reg = <528000>;
			clock-frequency = <528000>;
			nvidia,revision = <0x42>;
			nvidia,emc-min-mv = <1050>;
			nvidia,source = "pll_m";
			nvidia,src-sel-reg = <0x84000000>;
			nvidia,burst-regs-num = <100>;
			nvidia,emc-trimmers-num = <30>;
			nvidia,burst-up-down-regs-num = <11>;
			nvidia,emc-registers = <0x00000018 0x00000053
					0x00000000 0x00000011 0x00000006 0x00000006
					0x00000009 0x00000002 0x0000000d 0x00000006
					0x00000006 0x00000002 0x00000001 0x00000000
					0x00000005 0x0000000f 0x00000009 0x00010000
					0x00000000 0x00000006 0x00000012 0x00000fd6
					0x00000000 0x000003f5 0x00000002 0x0000000b
					0x00000001 0x00000000 0x00000050 0x00000012
					0x0000005a 0x00000200 0x00000004 0x00000004
					0x00000004 0x00000016 0x00000000 0x00000005
					0x00000006 0x00001017 0x00000000 0x00000020
					0x00000000 0x00005088 0xf0120091 0x00008000
					0x0000000a 0x0000000a 0x0000000a 0x0000000a
					0x00000000 0x00000000 0x00000000 0x00000000
					0x00000000 0x00000000 0x00000000 0x00000000
					0x001112a0 0x00000000 0x0000013d 0x00000000
					0x77ffc085 0x81f1f108 0x07077504 0x00000000
					0x0000003f 0x00000000 0x02000000 0x00000802
					0x00020000 0x00000100 0x016e000c 0x016e000c
					0x00000000 0x00000000 0x00000000 0x00000000
					0x80002062 0x1f7df7df 0x0000001f 0x0f000007
					0x80000190 0x00000002 0x00000003 0x0000000d
					0x00000008 0x0000000a 0x00000001 0x00000002
					0x00000009 0x00000002 0x00000002 0x00000005
					0x00000006 0x06050202 0x0010090d 0x7428180e
					0x001f0000 0x00040320>;
			nvidia,emc-trimmers-0 = <0x00000000 0x00000006
					0x00000008 0x00000007 0x00000004 0x0000000a
					0x0000000c 0x00000000 0x00000010 0x00249249
					0x20820800 0x0000000c 0xa0f10f0f 0x00000010
					0x00000909 0x00000000 0x00000000 0x00000010
					0x0000000a 0x0000000a 0x0000000a 0x0000000c
					0x0000000c 0x0000000c 0x00000000 0x00000000
					0x00000000 0x00000000 0x00000000 0x00000000>;
			nvidia,emc-trimmers-1 = <0x00000000 0x00000006
					0x00000008 0x00000007 0x00000004 0x0000000a
					0x0000000c 0x00000000 0x00000010 0x00249249
					0x20820800 0x0000000c 0xa8f10f0f 0x00000010
					0x00000909 0x00000000 0x00000000 0x00000010
					0x0000000a 0x0000000a 0x0000000a 0x0000000c
					0x0000000c 0x0000000c 0x00000000 0x00000000
					0x00000000 0x00000000 0x00000000 0x00000000>;
			nvidia,emc-burst-up-down-regs = <0x0000010e 0x000d000d
					0x000d000f 0x00100012 0x00000012 0x00120012
					0x00180012 0x00000018 0x00180018 0x00a3004d
					0x00a300a3 0x4E564441 0x04010700 0x02000400
					528000>;
			nvidia,emc-zcal-cnt-long = <0x00000042>;
			nvidia,emc-acal-interval = <0x001fffff>;
			nvidia,emc-cfg = <0x53000004>;
			nvidia,emc-mode-reset = <0x80000941>;
			nvidia,emc-mode-1 = <0x80100002>;
			nvidia,emc-mode-2 = <0x80200008>;
			nvidia,emc-mode-4 = <0x00000000>;
			nvidia,emc-clock-latency-change = <1440>;
		};
		emc-table@624000 {
			compatible = "nvidia,tegra11-emc-table";
			reg = <624000>;
			clock-frequency = <624000>;
			nvidia,revision = <0x42>;
			nvidia,emc-min-mv = <1100>;
			nvidia,source = "pll_c";
			nvidia,src-sel-reg = <0x24000000>;
			nvidia,burst-regs-num = <100>;
			nvidia,emc-trimmers-num = <30>;
			nvidia,burst-up-down-regs-num = <11>;
			nvidia,emc-registers = <0x0000001d 0x00000062
					0x00000000 0x00000014 0x00000007 0x00000007
					0x0000000b 0x00000003 0x00000010 0x00000007
					0x00000007 0x00000003 0x00000001 0x00000000
					0x00000005 0x0000000f 0x0000000a 0x00010000
					0x00000000 0x00000007 0x00000014 0x000012c3
					0x00000000 0x000004b0 0x00000002 0x0000000d
					0x00000001 0x00000000 0x0000005d 0x00000015
					0x0000006b 0x00000200 0x00000005 0x00000005
					0x00000005 0x00000019 0x00000000 0x00000006
					0x00000007 0x00001304 0x00000009 0x80000000
					0x00000000 0x0000ba88 0xf00d0191 0x00008000
					0x007fc008 0x007fc008 0x007fc008 0x007fc008
					0x00000000 0x00000000 0x00000000 0x00000000
					0x00000000 0x00000000 0x00000000 0x00000000
					0x001112a0 0x00000000 0x0000013d 0x00000000
					0x77ffc085 0x81f1f108 0x07077504 0x00000000
					0x0000003f 0x00000000 0x02000000 0x00000802
					0x00020000 0x00000100 0x0161000c 0x0161000c
					0x00000000 0x00000000 0x00000000 0x00000000
					0x80002617 0x1f7df7df 0x0000001f 0x06000009
					0x80000190 0x00000003 0x00000004 0x0000000f
					0x00000009 0x0000000c 0x00000002 0x00000003
					0x0000000b 0x00000002 0x00000002 0x00000005
					0x00000007 0x07050202 0x00130b0f 0x736a1d10
					0x001f0000 0x00040320>;
			nvidia,emc-trimmers-0 = <0x00000000 0x00000006
					0x00000009 0x00000008 0x00000004 0x007fc008
					0x0000000c 0x00000000 0x00000012 0x00249249
					0x20820800 0x0000000b 0xa0f10f0f 0x00000000
					0x00000909 0x00000000 0x00000000 0x00000000
					0x007fc008 0x007fc008 0x007fc008 0x0000000b
					0x0000000b 0x0000000b 0x00000000 0x00000000
					0x00000000 0x00000000 0x00000000 0x00000000>;
			nvidia,emc-trimmers-1 = <0x00000000 0x00000006
					0x00000009 0x00000008 0x00000004 0x007fc008
					0x0000000c 0x00000000 0x00000012 0x00249249
					0x20820800 0x0000000b 0xa8f10f0f 0x00000000
					0x00000909 0x00000000 0x00000000 0x00000000
					0x007fc008 0x007fc008 0x007fc008 0x0000000b
					0x0000000b 0x0000000b 0x00000000 0x00000000
					0x00000000 0x00000000 0x00000000 0x00000000>;
			nvidia,emc-burst-up-down-regs = <0x0000013f 0x000b000b
					0x000b000c 0x000e000f 0x0000000f 0x000f000f
					0x0014000f 0x00000014 0x00140014 0x008a0041
					0x008a008a 0x4E564441 0x04010700 0x02000400
					624000>;
			nvidia,emc-zcal-cnt-long = <0x00000042>;
			nvidia,emc-acal-interval = <0x001fffff>;
			nvidia,emc-cfg = <0x53200000>;
			nvidia,emc-mode-reset = <0x80000b61>;
			nvidia,emc-mode-1 = <0x80100002>;
			nvidia,emc-mode-2 = <0x80200410>;
			nvidia,emc-mode-4 = <0x00000000>;
			nvidia,emc-clock-latency-change = <1290>;
		};
		emc-table@792000 {
			compatible = "nvidia,tegra11-emc-table";
			reg = <792000>;
			clock-frequency = <792000>;
			nvidia,revision = <0x42>;
			nvidia,emc-min-mv = <1100>;
			nvidia,source = "pll_m";
			nvidia,src-sel-reg = <0x84000000>;
			nvidia,burst-regs-num = <100>;
			nvidia,emc-trimmers-num = <30>;
			nvidia,burst-up-down-regs-num = <11>;
			nvidia,emc-registers = <0x00000025 0x0000007d
					0x00000000 0x0000001a 0x00000009 0x00000008
					0x0000000d 0x00000004 0x00000013 0x00000009
					0x00000009 0x00000004 0x00000001 0x00000000
					0x00000006 0x0000000f 0x0000000b 0x00010000
					0x00000000 0x00000008 0x00000016 0x000017e1
					0x00000000 0x000005f8 0x00000003 0x00000011
					0x00000001 0x00000000 0x00000076 0x00000018
					0x00000087 0x00000200 0x00000005 0x00000005
					0x00000005 0x00000020 0x00000000 0x00000007
					0x00000008 0x00001822 0x00000000 0x80000000
					0x00000000 0x00005088 0xf0070191 0x00008000
					0x00004007 0x00004007 0x00004007 0x00004007
					0x00000000 0x00000000 0x00000000 0x00000000
					0x00000000 0x00000000 0x00000000 0x00000000
					0x001112a0 0x00000000 0x0000013d 0x00000000
					0x77ffc085 0x81f1f108 0x07077704 0x00000000
					0x0000003f 0x00000000 0x02000000 0x00000802
					0x00020000 0x00000100 0x0148000c 0x0148000c
					0x00000000 0x00000000 0x00000000 0x00000000
					0x80003012 0x1f7df7df 0x0000001f 0x0e00000b
					0x80000190 0x00000004 0x00000005 0x00000013
					0x0000000c 0x0000000f 0x00000002 0x00000003
					0x0000000c 0x00000002 0x00000002 0x00000006
					0x00000008 0x08060202 0x00160d13 0x72cc2414
					0x001f0000 0x00040000>;
			nvidia,emc-trimmers-0 = <0x00000000 0x00000006
					0x0000000a 0x00000008 0x00000006 0x00004007
					0x0000000d 0x00000000 0x00000014 0x00208208
					0x20820800 0x0000000a 0xa0f10f0f 0x0000000b
					0x00000b0b 0x00000000 0x00000000 0x0000000b
					0x00004007 0x00004007 0x00004007 0x0000000a
					0x0000000a 0x0000000a 0x00000000 0x00000000
					0x00000000 0x00000000 0x00000000 0x00000000>;
			nvidia,emc-trimmers-1 = <0x00000000 0x00000006
					0x0000000a 0x00000008 0x00000006 0x00004007
					0x0000000d 0x00000000 0x00000014 0x00208208
					0x20820800 0x0000000a 0xa8f10f0f 0x0000000b
					0x00000b0b 0x00000000 0x00000000 0x0000000b
					0x00004007 0x00004007 0x00004007 0x0000000a
					0x0000000a 0x0000000a 0x00000000 0x00000000
					0x00000000 0x00000000 0x00000000 0x00000000>;
			nvidia,emc-burst-up-down-regs = <0x00000196 0x00090009
					0x0009000a 0x000b000c 0x0000000c 0x000c000c
					0x0010000c 0x00000010 0x00100010 0x006d0033
					0x006d006d 0x4E564441 0x04010700 0x02000400
					792000>;
			nvidia,emc-zcal-cnt-long = <0x00000042>;
			nvidia,emc-acal-interval = <0x001fffff>;
			nvidia,emc-cfg = <0x53000000>;
			nvidia,emc-mode-reset = <0x80000d71>;
			nvidia,emc-mode-1 = <0x80100002>;
			nvidia,emc-mode-2 = <0x80200418>;
			nvidia,emc-mode-4 = <0x00000000>;
			nvidia,emc-clock-latency-change = <1200>;
		};
	};

	mipical {
		compatible = "nvidia,tegra114-mipical";
		reg = <0x700e3000 0x00040000>;
	};

	host1x {
		/* tegradc.0 */
		dc@54200000 {
			status = "okay";
			nvidia,dc-flags = "dc_flag_en";
			nvidia,emc-clk-rate = <204000000>;
			nvidia,cmu-enable = <0>;
			dc-default-out {
				nvidia,out-type = "dsi";
				nvidia,out-width = <94>;
				nvidia,out-height = <150>;
				nvidia,out-flags = "continuous_initialized";
				nvidia,out-parent-clk = "pll_d_out0";
			};
			display-timings {
				800x1200-32 {
					clock-frequency = <70666000>;
					hactive = <800>;
					vactive = <1280>;
					hfront-porch = <32>;
					hback-porch = <57>;
					hsync-len = <1>;
					vfront-porch = <28>;
					vback-porch = <14>;
					vsync-len = <1>;
					nvidia,h-ref-to-sync = <10>;
					nvidia,v-ref-to-sync = <1>;
				};
			};
			framebuffer-data {
				nvidia,fb-bpp = <32>; /* bits per pixel */
				nvidia,fb-flags = "flip_on_probe";
				nvidia,fb-xres = <800>;
				nvidia,fb-yres = <1280>;
			};
			smartdimmer {
				status = "disabled";
				nvidia,use-auto-pwm = <0>;
				nvidia,hw-update-delay = <0>;
				nvidia,bin-width = "-1";
				nvidia,aggressiveness = <5>;
				nvidia,use-vid-luma = <0>;
				nvidia,phase-in-settings = <0>;
				nvidia,phase-in-adjustments = <0>;
				nvidia,k-limit-enable = <1>;
				nvidia,k-limit = <200>;
				nvidia,sd-window-enable = <0>;
				nvidia,soft-clipping-enable= <1>;
				nvidia,soft-clipping-threshold = <128>;
				nvidia,smooth-k-enable = <1>;
				nvidia,smooth-k-incr = <4>;
				nvidia,coeff = <5 9 2>;
				nvidia,fc = <0 0>;
				nvidia,blp = <1024 255>;
				nvidia,bltf = <57 65 73 82
						  92 103 114 125
						  138 150 164 178
						  193 208 224 241>;
				nvidia,lut = <255 255 255
						 199 199 199
						 153 153 153
						 116 116 116
						 85 85 85
						 59 59 59
						 36 36 36
						 17 17 17
						 0 0 0>;
				nvidia,use-vpulse2 = <1>;
				nvidia,bl-device-name = "pwm-backlight";
			};
			cmu {
				nvidia,cmu-csc = < 0x106 0x3EB 0x00E
						   0x3F8 0x11B 0x3EB
						   0x003 0x001 0x0FB >;
				nvidia,cmu-lut2 = < 0 2 4 7 9 11 13 14
						    16 17 19 20 21 22 23 24
						    25 26 27 27 28 28 29 29
						    29 30 30 30 30 31 31 31
						    31 31 31 31 31 32 32 32
						    32 32 32 33 33 33 33 33
						    34 34 34 34 35 35 35 35
						    36 36 36 37 37 37 38 38
						    38 39 39 39 40 40 40 41
						    41 41 42 42 42 43 43 44
						    44 44 45 45 45 46 46 46
						    47 47 47 48 48 48 49 49
						    49 49 50 50 50 51 51 51
						    51 52 52 52 52 53 53 53
						    53 54 54 54 54 54 55 55
						    55 55 55 56 56 56 56 56
						    57 57 57 57 57 57 58 58
						    58 58 58 58 59 59 59 59
						    59 59 59 60 60 60 60 60
						    60 60 60 61 61 61 61 61
						    61 61 61 62 62 62 62 62
						    62 62 62 63 63 63 63 63
						    63 63 63 63 64 64 64 64
						    64 64 64 64 65 65 65 65
						    65 65 65 65 66 66 66 66
						    66 66 66 66 67 67 67 67
						    67 67 67 67 68 68 68 68
						    68 68 68 68 69 69 69 69
						    69 69 69 69 70 70 70 70
						    70 70 70 71 71 71 71 71
						    71 71 71 72 72 72 72 72
						    72 72 72 73 73 73 73 73
						    73 73 74 74 74 74 74 74
						    74 74 75 75 75 75 75 75
						    75 75 76 76 76 76 76 76
						    76 76 77 77 77 77 77 77
						    77 77 78 78 78 78 78 78
						    78 78 79 79 79 79 79 79
						    79 79 80 80 80 80 80 80
						    80 80 80 81 81 81 81 81
						    81 81 81 82 82 82 82 82
						    82 82 82 82 83 83 83 83
						    83 83 83 83 83 83 84 84
						    84 84 84 84 84 84 84 85
						    85 85 85 85 85 85 85 85
						    85 86 86 86 86 86 86 86
						    86 86 86 87 87 87 87 87
						    87 87 87 87 87 87 88 88
						    88 88 88 88 88 88 88 88
						    89 89 89 89 89 89 89 89
						    89 89 89 90 90 90 90 90
						    90 90 90 90 90 90 91 91
						    91 91 91 91 91 91 91 91
						    91 91 92 92 92 92 92 92
						    92 92 92 92 92 92 93 93
						    93 93 93 93 93 93 93 93
						    93 94 94 94 94 94 94 94
						    94 94 94 94 94 95 95 95
						    95 95 95 95 95 95 95 95
						    95 95 96 96 96 96 96 96
						    96 96 96 96 96 96 97 97
						    97 97 97 97 97 97 97 97
						    97 97 98 98 98 98 98 98
						    98 98 98 98 98 98 98 99
						    99 100 100 101 102 102 103 104
						   104 105 105 106 107 107 108 108
						   109 110 110 111 111 112 112 113
						   114 114 115 115 116 116 117 117
						   118 118 119 119 120 120 121 121
						   122 122 123 123 124 124 125 125
						   126 126 127 127 128 128 129 129
						   130 130 131 131 132 132 133 133
						   134 134 134 135 135 136 136 137
						   137 138 138 139 139 139 140 140
						   141 141 142 142 142 143 143 144
						   144 144 145 145 146 146 146 147
						   147 148 148 148 149 149 150 150
						   150 151 151 151 152 152 153 153
						   153 154 154 154 155 155 156 156
						   156 157 157 157 158 158 159 159
						   159 160 160 160 161 161 162 162
						   162 163 163 164 164 164 165 165
						   166 166 166 167 167 168 168 168
						   169 169 170 170 170 171 171 172
						   172 172 173 173 174 174 174 175
						   175 176 176 176 177 177 178 178
						   178 179 179 179 180 180 181 181
						   181 182 182 182 183 183 183 184
						   184 185 185 185 186 186 186 187
						   187 187 188 188 189 189 189 190
						   190 190 191 191 191 192 192 192
						   193 193 193 194 194 195 195 195
						   196 196 196 197 197 197 198 198
						   198 199 199 199 200 200 200 201
						   201 201 202 202 202 203 203 203
						   204 204 204 205 205 205 206 206
						   206 207 207 207 208 208 208 209
						   209 209 210 210 210 211 211 211
						   211 212 212 212 213 213 213 214
						   214 214 214 215 215 215 216 216
						   216 216 217 217 217 218 218 218
						   218 219 219 219 220 220 220 220
						   221 221 221 222 222 222 222 223
						   223 223 223 224 224 224 225 225
						   225 225 226 226 226 226 227 227
						   227 227 228 228 228 228 229 229
						   229 229 230 230 230 230 231 231
						   231 231 232 232 232 232 233 233
						   233 233 234 234 234 234 235 235
						   235 235 236 236 236 236 237 237
						   237 237 238 238 238 238 239 239
						   239 239 240 240 240 240 241 241
						   241 241 241 242 242 242 242 243
						   243 243 243 244 244 244 244 245
						   245 245 245 245 246 246 246 246
						   247 247 247 247 248 248 248 248
						   249 249 249 249 249 250 250 250
						   250 251 251 251 251 251 252 252
						   252 252 253 253 253 253 253 254
						   254 254 254 255 255 255 255 255 >;
			};
		};

		/* tegradc.1 */
		dc@54240000 {
			status = "okay";
			nvidia,emc-clk-rate = <300000000>;
			nvidia,cmu-enable = <1>;
			dc-default-out {
				nvidia,out-type = "hdmi";
				nvidia,out-flags = "hotplug_high";
				nvidia,out-parent-clk = "pll_d2_out0";
				nvidia,out-max-pixclk = <148500>;
				nvidia,out-align = "msb";
				nvidia,out-order = "rtob"; /*red to blue*/
				nvidia,out-tmds-cfg {
					tmds-cfg@0 {
						pclk = <27000000>;
						pll0 = <0x01003010>;
						pll1 = <0x00301b00>;
						pe-current = <0x00000000>;
						drive-current = <0x23232323>;
						peak-current = <0x00000000>;
					};
					tmds-cfg@1 {
						pclk = <74250000>;
						pll0 = <0x01003110>;
						pll1 = <0x00301b00>;
						pe-current = <0x00000000>;
						drive-current = <0x21212121>;
						peak-current = <0x03030303>;
					};
					tmds-cfg@2 {
						pclk = <148500000>;
						pll0 = <0x01003310>;
						pll1 = <0x00301b00>;
						pe-current = <0x00000000>;
						drive-current = <0x24242424>;
						peak-current = <0x03030303>;
					};
					tmds-cfg@3 {
						pclk = <0x7fffffff>;
						pll0 = <0x01003f10>;
						pll1 = <0x13300b00>;
						pe-current = <0x00000000>;
						drive-current = <0x24242424>;
						peak-current = <0x07070707>;
					};
				};
			};
			framebuffer-data {
				nvidia,fb-bpp = <32>; /* bits per pixel */
				nvidia,fb-flags = "flip_on_probe";
				nvidia,fb-xres = <1024>;
				nvidia,fb-yres = <600>;
			};
		};
		dsi {
			status = "okay";
			nvidia,panel = <&panel>;
			nvidia,dsi-n-data-lanes = <4>;
			nvidia,dsi-video-burst-mode = "none_burst";
			nvidia,dsi-pixel-format = "24_p";
			nvidia,dsi-ref-rate = <60>;
			nvidia,dsi-virtual-ch = "vc0";
			nvidia,dsi-instance = <0>; /* 0 or 1 */
			nvidia,dsi-panel-reset = <0>;
			nvidia,dsi-power-saving-suspend = <1>;
			nvidia,dsi-video-data-type = "video";
			nvidia,dsi-video-clk-mode = "txonly";
			nvidia,dsi-phy-datzero = <270>;
			nvidia,dsi-phy-hsprepare = <30>;
			nvidia,dsi-phy-clkzero = <330>;
			nvidia,dsi-phy-clkprepare = <27>;
		};
		hdmi {
			status = "okay";
			nvidia,regulators = "avdd_hdmi",
					    "avdd_hdmi_pll",
					    "vdd_hdmi_5v0";
			nvidia,ddc-i2c-bus = <&hdmi_ddc>;
			nvidia,hpd-gpio = <&gpio 111 1>;
			nvidia,hotplug-report = <1>;
		};
	};
	pwm-bl {
		status = "okay";
		nvidia,panel-pwm-bl = <&panelpwmbl>;
		nvidia,pwm-id = <1>;
		nvidia,max-brightness = <255>;
		nvidia,dft-brightness = <153>;
		nvidia,dft-charge-brightness = <60>;
		nvidia,pwm-period-ns = <1000000>;
		nvidia,disable-edp-throttle = <1>;
		nvidia,edp-states = <1711 1390 1057 713 360 0>;
		nvidia,edp-brightness = <255 204 153 101 50 0>;
		nvidia,pwm-gpio = <&gpio 57 0>; /* gpio PH1 */
	};

	panel: panel {
		compatible = "lgd,tegratab";
		status = "okay";
		nvidia,regulators = "avdd_lcd",
				    "vdd_lcd_bl_en",
				    "dvdd_lcd";
	};

	panelpwmbl: panelpwmbl {
		compatible = "lgd-pwm-bl,tegratab";
		status = "okay";
		nvidia,bl-output = < 0 1 2 3 4 6 7 8 9 10
				     11 12 13 14 15 16 16 17 18 19
				     20 21 22 23 24 25 25 26 27 28
				     29 30 31 32 33 34 35 36 37 38
				     39 40 41 42 43 44 45 46 47 48
				     49 50 51 52 53 54 55 56 57 58
				     59 60 61 62 63 64 65 66 67 68
				     69 70 71 72 73 74 74 75 76 77
				     78 79 80 81 82 83 84 85 86 87
				     88 89 90 91 92 93 94 95 96 97
				     98 99 100 101 102 103 104 105 106 107
				     108 109 110 111 112 113 114 115 116 117
				     118 119 120 121 122 123 124 125 126 127
				     128 129 130 131 132 133 134 135 136 137
				     138 139 140 141 142 143 144 145 146 147
				     148 149 150 151 152 153 154 155 156 157
				     158 159 160 161 162 164 165 166 167 168
				     169 170 171 172 173 174 175 176 177 178
				     179 180 181 182 183 184 185 186 187 188
				     189 190 191 192 193 194 195 196 197 198
				     199 200 201 202 203 205 206 207 208 209
				     210 211 212 213 214 215 216 217 218 219
				     220 221 222 223 224 225 226 227 228 229
				     230 231 232 233 234 236 237 238 239 240
				     241 242 243 244 245 246 247 248 249 250
				     251 252 253 253 254 255 >;
	};

	/* GEN1 */
	i2c@7000c000 {
		status = "okay";
		clock-frequency = <100000>;

		/* ALS sensor */
		cm3217@10 {
			compatible = "capella,cm3217";
			reg = <0x10>;
			levels = <10 160 225 320 640 1280 2600 5800 8000 10240>;
			golden_adc = <0>;
		};

		/* Compass sensor */
		ak8963c@0d {
			compatible = "ak,ak8963";
			reg = <0x0d>;
			orientation = [ff 00 00 00 01 00 00 00 ff];
			config = "mpu";
			sec-slave-id = <18>;
		};
	};

	/* CAM */
	i2c@7000c500 {
		status = "okay";
		ad5823@0c {
			compatible = "nvidia,ad5823";
			reg = <0x0c>;
			af-pwdn-gpios = <&gpio 223 0>; /* gpio PBB7 */
		};
		ov5693@10 {
			compatible = "nvidia,ov5693";
			reg = <0x10>;
			nvidia,num = <5693>;
			nvidia,dev-name = "camera";
			nvidia,use-vcm-vdd;
			reset-gpios = <&gpio 221 0>; /* gpio PBB5 */
		};
	};
	/* DDC */
	hdmi_ddc: i2c@7000c700 {
		status = "okay";
		clock-frequency = <100000>;
	};

	pwfm@0x7000a010 {
		status = "okay";
	};
};
